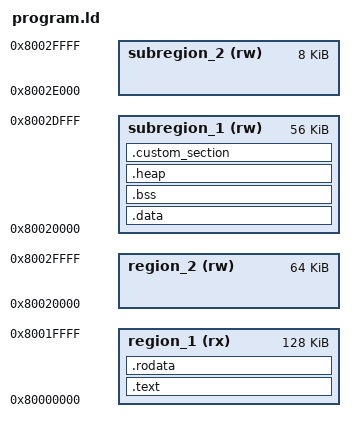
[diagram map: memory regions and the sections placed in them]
# DO NOT EDIT. AUTOGENERATED BY 'rv-runtime-generator'
OUTPUT_ARCH(riscv)
ENTRY(_start)
MEMORY {
    region_1 (rx) : ORIGIN = 0x80000000, LENGTH = 0x20000
    region_2 (rw) : ORIGIN = 0x80020000, LENGTH = 0x10000
    subregion_1 (rw) : ORIGIN = 0x80020000, LENGTH = 0xe000
    subregion_2 (rw) : ORIGIN = 0x8002e000, LENGTH = 0x2000
}
SECTIONS {
    .text : ALIGN(4096) {
        _stext = .;
        *(.text.entry .text.entry.*)
        *(.text.custom_reset_entry .text.custom_reset_entry.*)
        *(.text .text.*)
        . = ALIGN(4096);
        _etext = .;
    } >region_1
    .rodata : ALIGN(4096) {
        _srodata = .;
        *(.rodata .rodata.*)
        *(.srodata .srodata.*)
        . = ALIGN(131072);
        _erodata = .;
    } >region_1
    .data : ALIGN(4096) {
        _sdata = .;
        _global_pointer = . + 0x800;
        *(.data .data.*)
        *(.sdata .sdata.*)
        . = ALIGN(4096);
        _edata = .;
    } >subregion_1
    .bss (NOLOAD): ALIGN(4096) {
        _sbss = .;
        *(.bss .bss.*)
        *(.sbss .sbss.*)
        . = ALIGN(8192);
        _sstack = .;
        . += 0x8000;
        _stack_top = .;
        _estack = .;
        . = ALIGN(4096);
        _ebss = .;
    } >subregion_1
    .heap (NOLOAD): ALIGN(4096) {
        _sheap = .;
        . += 0x1000;
        . = ALIGN(4096);
        _eheap = .;
    } >subregion_1
    .custom_section (NOLOAD): ALIGN(4096) {
        _scustom_section = .;
        . += 0x1000;
        . = ALIGN(4096);
        _ecustom_section = .;
    } >subregion_1
    /DISCARD/ : {
        *(.eh_frame .eh_frame.*)
    }
    _sprogram = _stext;
    _eprogram = _ecustom_section;
    _sregion_1 = 0x80000000;
    _eregion_1 = 0x80020000;
    _sregion_2 = 0x80020000;
    _eregion_2 = 0x80030000;
    _ssubregion_1 = 0x80020000;
    _esubregion_1 = 0x8002e000;
    _ssubregion_2 = 0x8002e000;
    _esubregion_2 = 0x80030000;
}
ASSERT(_sregion_1 <= _stext, "region_1 underflow")
ASSERT(_eregion_1 >= _erodata, "region_1 overflow")
ASSERT(_ssubregion_1 <= _sdata, "subregion_1 underflow")
ASSERT(_esubregion_1 >= _ecustom_section, "subregion_1 overflow")
